AUTOSAR XML (schema 4-3-0)
package /Impl_CGW_ARPkg
  swc implementation Impl_SWC_CGW_type: programming-language=C, sw-version=1.0.0, vendor-id=0, behavior=SWC_CGW_type_IB
    code-descriptors:
      code SRC: artifact-descriptors=autosar-engineering-object={short-label=EngObject, category=SWSRC}
    resource consumption ResourceConsumption
      memory section MEM_SWC_CGW_CAL: size=0, sw-addrmethod=CAL, symbol=CAL
      memory section MEM_SWC_CGW_CODE: size=0, sw-addrmethod=CODE, symbol=CODE
package /SWC_CGW_ARPkg
  trigger interface IF_ExtTrig_CGW
    trigger Trig_CGW
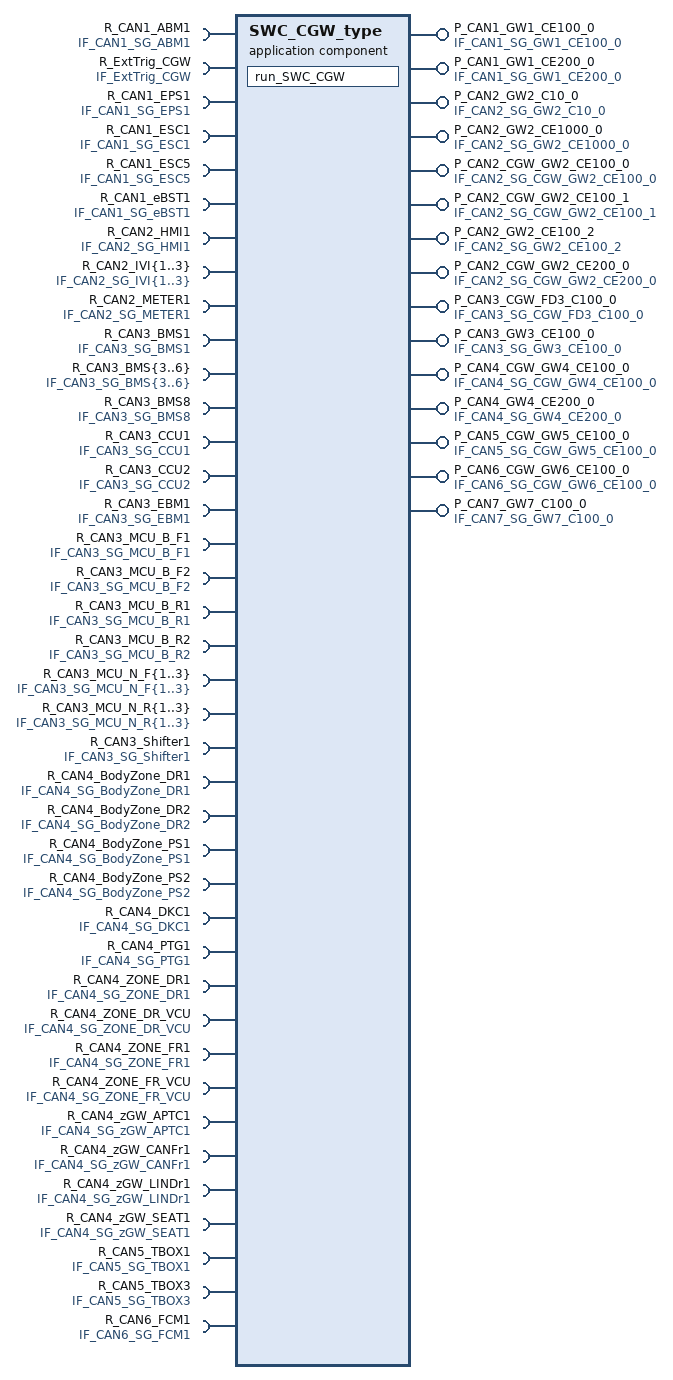
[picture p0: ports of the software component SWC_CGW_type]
  application sw component type SWC_CGW_type
    15 x provide port:
      P_CAN1_GW1_CE100_0: provided-interface=IF_CAN1_SG_GW1_CE100_0
      P_CAN1_GW1_CE200_0: provided-interface=IF_CAN1_SG_GW1_CE200_0
      P_CAN2_GW2_C10_0: provided-interface=IF_CAN2_SG_GW2_C10_0
      P_CAN2_GW2_CE1000_0: provided-interface=IF_CAN2_SG_GW2_CE1000_0
      P_CAN2_CGW_GW2_CE100_0: provided-interface=IF_CAN2_SG_CGW_GW2_CE100_0
      P_CAN2_CGW_GW2_CE100_1: provided-interface=IF_CAN2_SG_CGW_GW2_CE100_1
      P_CAN2_GW2_CE100_2: provided-interface=IF_CAN2_SG_GW2_CE100_2
      P_CAN2_CGW_GW2_CE200_0: provided-interface=IF_CAN2_SG_CGW_GW2_CE200_0
      P_CAN3_CGW_FD3_C100_0: provided-interface=IF_CAN3_SG_CGW_FD3_C100_0
      P_CAN3_GW3_CE100_0: provided-interface=IF_CAN3_SG_GW3_CE100_0
      P_CAN4_CGW_GW4_CE100_0: provided-interface=IF_CAN4_SG_CGW_GW4_CE100_0
      P_CAN4_GW4_CE200_0: provided-interface=IF_CAN4_SG_GW4_CE200_0
      P_CAN5_CGW_GW5_CE100_0: provided-interface=IF_CAN5_SG_CGW_GW5_CE100_0
      P_CAN6_CGW_GW6_CE100_0: provided-interface=IF_CAN6_SG_CGW_GW6_CE100_0
      P_CAN7_GW7_C100_0: provided-interface=IF_CAN7_SG_GW7_C100_0
    48 x require port:
      R_CAN1_ABM1: required-interface=IF_CAN1_SG_ABM1
      R_ExtTrig_CGW: required-interface=IF_ExtTrig_CGW
      R_CAN1_EPS1: required-interface=IF_CAN1_SG_EPS1
      R_CAN1_ESC1: required-interface=IF_CAN1_SG_ESC1
      R_CAN1_ESC5: required-interface=IF_CAN1_SG_ESC5
      R_CAN1_eBST1: required-interface=IF_CAN1_SG_eBST1
      R_CAN2_HMI1: required-interface=IF_CAN2_SG_HMI1
      R_CAN2_IVI{1..3}: required-interface=IF_CAN2_SG_IVI{1..3}
      R_CAN2_METER1: required-interface=IF_CAN2_SG_METER1
      R_CAN3_BMS1: required-interface=IF_CAN3_SG_BMS1
      R_CAN3_BMS{3..6}: required-interface=IF_CAN3_SG_BMS{3..6}
      R_CAN3_BMS8: required-interface=IF_CAN3_SG_BMS8
      R_CAN3_CCU1: required-interface=IF_CAN3_SG_CCU1
      R_CAN3_CCU2: required-interface=IF_CAN3_SG_CCU2
      R_CAN3_EBM1: required-interface=IF_CAN3_SG_EBM1
      R_CAN3_MCU_B_F1: required-interface=IF_CAN3_SG_MCU_B_F1
      R_CAN3_MCU_B_F2: required-interface=IF_CAN3_SG_MCU_B_F2
      R_CAN3_MCU_B_R1: required-interface=IF_CAN3_SG_MCU_B_R1
      R_CAN3_MCU_B_R2: required-interface=IF_CAN3_SG_MCU_B_R2
      R_CAN3_MCU_N_F{1..3}: required-interface=IF_CAN3_SG_MCU_N_F{1..3}
      R_CAN3_MCU_N_R{1..3}: required-interface=IF_CAN3_SG_MCU_N_R{1..3}
      R_CAN3_Shifter1: required-interface=IF_CAN3_SG_Shifter1
      R_CAN4_BodyZone_DR1: required-interface=IF_CAN4_SG_BodyZone_DR1
      R_CAN4_BodyZone_DR2: required-interface=IF_CAN4_SG_BodyZone_DR2
      R_CAN4_BodyZone_PS1: required-interface=IF_CAN4_SG_BodyZone_PS1
      R_CAN4_BodyZone_PS2: required-interface=IF_CAN4_SG_BodyZone_PS2
      R_CAN4_DKC1: required-interface=IF_CAN4_SG_DKC1
      R_CAN4_PTG1: required-interface=IF_CAN4_SG_PTG1
      R_CAN4_ZONE_DR1: required-interface=IF_CAN4_SG_ZONE_DR1
      R_CAN4_ZONE_DR_VCU: required-interface=IF_CAN4_SG_ZONE_DR_VCU
      R_CAN4_ZONE_FR1: required-interface=IF_CAN4_SG_ZONE_FR1
      R_CAN4_ZONE_FR_VCU: required-interface=IF_CAN4_SG_ZONE_FR_VCU
      R_CAN4_zGW_APTC1: required-interface=IF_CAN4_SG_zGW_APTC1
      R_CAN4_zGW_CANFr1: required-interface=IF_CAN4_SG_zGW_CANFr1
      R_CAN4_zGW_LINDr1: required-interface=IF_CAN4_SG_zGW_LINDr1
      R_CAN4_zGW_SEAT1: required-interface=IF_CAN4_SG_zGW_SEAT1
      R_CAN5_TBOX1: required-interface=IF_CAN5_SG_TBOX1
      R_CAN5_TBOX3: required-interface=IF_CAN5_SG_TBOX3
      R_CAN6_FCM1: required-interface=IF_CAN6_SG_FCM1
    behavior SWC_CGW_type_IB: handle-termination-and-restart=NO-SUPPORT
      external trigger occurred event ETE_CGW: start-on-event=run_SWC_CGW, trigger=R_ExtTrig_CGW.Trig_CGW
      runnable run_SWC_CGW
        data-read-access:
          47 x access:
            DA_R_CAN1_ABM1: accessed-variable=R_CAN1_ABM1.CAN1_SG_ABM1
            DA_R_CAN1_EPS1: accessed-variable=R_CAN1_EPS1.CAN1_SG_EPS1
            DA_R_CAN1_ESC1: accessed-variable=R_CAN1_ESC1.CAN1_SG_ESC1
            DA_R_CAN1_ESC5: accessed-variable=R_CAN1_ESC5.CAN1_SG_ESC5
            DA_R_CAN1_eBST1: accessed-variable=R_CAN1_eBST1.CAN1_SG_eBST1
            DA_R_CAN2_HMI1: accessed-variable=R_CAN2_HMI1.CAN2_SG_HMI1
            DA_R_CAN2_IVI{1..3}: accessed-variable=R_CAN2_IVI{1..3}.CAN2_SG_IVI{1..3}
            DA_R_CAN2_METER1: accessed-variable=R_CAN2_METER1.CAN2_SG_METER1
            DA_R_CAN3_BMS1: accessed-variable=R_CAN3_BMS1.CAN3_SG_BMS1
            DA_R_CAN3_BMS{3..6}: accessed-variable=R_CAN3_BMS{3..6}.CAN3_SG_BMS{3..6}
            DA_R_CAN3_BMS8: accessed-variable=R_CAN3_BMS8.CAN3_SG_BMS8
            DA_R_CAN3_CCU1: accessed-variable=R_CAN3_CCU1.CAN3_SG_CCU1
            DA_R_CAN3_CCU2: accessed-variable=R_CAN3_CCU2.CAN3_SG_CCU2
            DA_R_CAN3_EBM1: accessed-variable=R_CAN3_EBM1.CAN3_SG_EBM1
            DA_R_CAN3_MCU_B_F1: accessed-variable=R_CAN3_MCU_B_F1.CAN3_SG_MCU_B_F1
            DA_R_CAN3_MCU_B_F2: accessed-variable=R_CAN3_MCU_B_F2.CAN3_SG_MCU_B_F2
            DA_R_CAN3_MCU_B_R1: accessed-variable=R_CAN3_MCU_B_R1.CAN3_SG_MCU_B_R1
            DA_R_CAN3_MCU_B_R2: accessed-variable=R_CAN3_MCU_B_R2.CAN3_SG_MCU_B_R2
            DA_R_CAN3_MCU_N_F{1..3}: accessed-variable=R_CAN3_MCU_N_F{1..3}.CAN3_SG_MCU_N_F{1..3}
            DA_R_CAN3_MCU_N_R{1..3}: accessed-variable=R_CAN3_MCU_N_R{1..3}.CAN3_SG_MCU_N_R{1..3}
            DA_R_CAN3_Shifter1: accessed-variable=R_CAN3_Shifter1.CAN3_SG_Shifter1
            DA_R_CAN4_BodyZone_DR1: accessed-variable=R_CAN4_BodyZone_DR1.CAN4_SG_BodyZone_DR1
            DA_R_CAN4_BodyZone_DR2: accessed-variable=R_CAN4_BodyZone_DR2.CAN4_SG_BodyZone_DR2
            DA_R_CAN4_BodyZone_PS1: accessed-variable=R_CAN4_BodyZone_PS1.CAN4_SG_BodyZone_PS1
            DA_R_CAN4_BodyZone_PS2: accessed-variable=R_CAN4_BodyZone_PS2.CAN4_SG_BodyZone_PS2
            DA_R_CAN4_DKC1: accessed-variable=R_CAN4_DKC1.CAN4_SG_DKC1
            DA_R_CAN4_PTG1: accessed-variable=R_CAN4_PTG1.CAN4_SG_PTG1
            DA_R_CAN4_ZONE_DR1: accessed-variable=R_CAN4_ZONE_DR1.CAN4_SG_ZONE_DR1
            DA_R_CAN4_ZONE_DR_VCU: accessed-variable=R_CAN4_ZONE_DR_VCU.CAN4_SG_ZONE_DR_VCU
            DA_R_CAN4_ZONE_FR1: accessed-variable=R_CAN4_ZONE_FR1.CAN4_SG_ZONE_FR1
            DA_R_CAN4_ZONE_FR_VCU: accessed-variable=R_CAN4_ZONE_FR_VCU.CAN4_SG_ZONE_FR_VCU
            DA_R_CAN4_zGW_APTC1: accessed-variable=R_CAN4_zGW_APTC1.CAN4_SG_zGW_APTC1
            DA_R_CAN4_zGW_CANFr1: accessed-variable=R_CAN4_zGW_CANFr1.CAN4_SG_zGW_CANFr1
            DA_R_CAN4_zGW_LINDr1: accessed-variable=R_CAN4_zGW_LINDr1.CAN4_SG_zGW_LINDr1
            DA_R_CAN4_zGW_SEAT1: accessed-variable=R_CAN4_zGW_SEAT1.CAN4_SG_zGW_SEAT1
            DA_R_CAN5_TBOX1: accessed-variable=R_CAN5_TBOX1.CAN5_SG_TBOX1
            DA_R_CAN5_TBOX3: accessed-variable=R_CAN5_TBOX3.CAN5_SG_TBOX3
            DA_R_CAN6_FCM1: accessed-variable=R_CAN6_FCM1.CAN6_SG_FCM1
        data-write-access:
          15 x access:
            DA_P_CAN1_GW1_CE100_0: accessed-variable=P_CAN1_GW1_CE100_0.CAN1_SG_GW1_CE100_0
            DA_P_CAN1_GW1_CE200_0: accessed-variable=P_CAN1_GW1_CE200_0.CAN1_SG_GW1_CE200_0
            DA_P_CAN2_GW2_C10_0: accessed-variable=P_CAN2_GW2_C10_0.CAN2_SG_GW2_C10_0
            DA_P_CAN2_GW2_CE1000_0: accessed-variable=P_CAN2_GW2_CE1000_0.CAN2_SG_GW2_CE1000_0
            DA_P_CAN2_CGW_GW2_CE100_0: accessed-variable=P_CAN2_CGW_GW2_CE100_0.CAN2_SG_CGW_GW2_CE100_0
            DA_P_CAN2_CGW_GW2_CE100_1: accessed-variable=P_CAN2_CGW_GW2_CE100_1.CAN2_SG_CGW_GW2_CE100_1
            DA_P_CAN2_GW2_CE100_2: accessed-variable=P_CAN2_GW2_CE100_2.CAN2_SG_GW2_CE100_2
            DA_P_CAN2_CGW_GW2_CE200_0: accessed-variable=P_CAN2_CGW_GW2_CE200_0.CAN2_SG_CGW_GW2_CE200_0
            DA_P_CAN3_CGW_FD3_C100_0: accessed-variable=P_CAN3_CGW_FD3_C100_0.CAN3_SG_CGW_FD3_C100_0
            DA_P_CAN3_GW3_CE100_0: accessed-variable=P_CAN3_GW3_CE100_0.CAN3_SG_GW3_CE100_0
            DA_P_CAN4_CGW_GW4_CE100_0: accessed-variable=P_CAN4_CGW_GW4_CE100_0.CAN4_SG_CGW_GW4_CE100_0
            DA_P_CAN4_GW4_CE200_0: accessed-variable=P_CAN4_GW4_CE200_0.CAN4_SG_GW4_CE200_0
            DA_P_CAN5_CGW_GW5_CE100_0: accessed-variable=P_CAN5_CGW_GW5_CE100_0.CAN5_SG_CGW_GW5_CE100_0
            DA_P_CAN6_CGW_GW6_CE100_0: accessed-variable=P_CAN6_CGW_GW6_CE100_0.CAN6_SG_CGW_GW6_CE100_0
            DA_P_CAN7_GW7_C100_0: accessed-variable=P_CAN7_GW7_C100_0.CAN7_SG_GW7_C100_0
